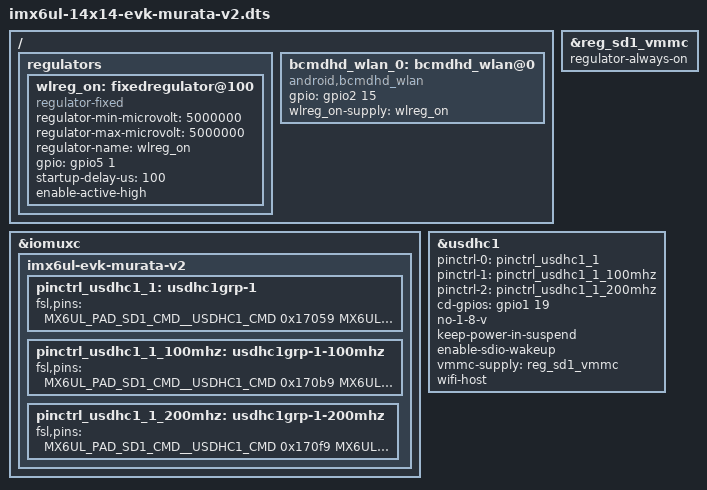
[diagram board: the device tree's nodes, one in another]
/*
 * Copyright (C) 2015 Freescale Semiconductor, Inc.
 *
 * This program is free software; you can redistribute it and/or modify
 * it under the terms of the GNU General Public License version 2 as
 * published by the Free Software Foundation.
 */

/* NOTE: This DTS file is written for plugging in Murata Wi-Fi/BT EVK into Slot SD1 */
/* and using Murata i.MX InterConnect Ver 2.0 Adapter. Bluetooth UART & control signals  */
/* are connected via ribbon cable (J1701 connector).  Default configuration does not enable OOB IRQ. */
/* If OOB IRQ (WL_HOST_WAKE) is needed then rework is required (reference Murata Hardware User Manual). */
#include "imx6ul-14x14-evk.dts"

/ {
	regulators {
		/* Murata -- add wlreg_on definition */
		wlreg_on: fixedregulator@100 {
			compatible = "regulator-fixed";
			regulator-min-microvolt = <5000000>;
			regulator-max-microvolt = <5000000>;
			regulator-name = "wlreg_on";
			gpio = <&gpio5 1 0>; /* WL_REG_ON: SNVS_TAMPER1 (gpio5_1) */
			startup-delay-us = <100>; /* WL_REG_ON needs 61 usec delay */ 
			enable-active-high;
		};
	};

	/* Murata -- define hook for BCMDHD driver.   */
	/* Include WL_HOST_WAKE and WL_REG_ON GPIO's. */
	bcmdhd_wlan_0: bcmdhd_wlan@0 {
		compatible = "android,bcmdhd_wlan";
		/* WL_HOST_WAKE: ENET2_RX_ER (gpio2_15) */
		gpio = <&gpio2 15 0>;
		wlreg_on-supply = <&wlreg_on>;
	};
};

&iomuxc {
	imx6ul-evk-murata-v2 {
		/* Murata -- modify MUXing to add WL_REG_ON and WL_HOST_WAKE for Ver 2.0 Adapter Only.  */ 
		/* Can add BT_HOST_WAKE and BT_DEV_WAKE later -- if rework done */
		/* Do not MUX WL_HOST_WAKE for now -- disrupts ethernet operation. */
		pinctrl_usdhc1_1: usdhc1grp-1 {
			fsl,pins = <
				MX6UL_PAD_SD1_CMD__USDHC1_CMD     0x17059
				MX6UL_PAD_SD1_CLK__USDHC1_CLK     0x10071 /* Murata: FSL Fix for drive strength; was 0x10059  */
				MX6UL_PAD_SD1_DATA0__USDHC1_DATA0 0x17059
				MX6UL_PAD_SD1_DATA1__USDHC1_DATA1 0x17059
				MX6UL_PAD_SD1_DATA2__USDHC1_DATA2 0x17059
				MX6UL_PAD_SD1_DATA3__USDHC1_DATA3 0x17059
				MX6UL_PAD_SNVS_TAMPER1__GPIO5_IO01 0x03029 /* Add MUXing for WL_REG_ON */
//				MX6UL_PAD_ENET2_RX_ER__GPIO2_IO15  0x13041 /* Add MUXing for WL_HOST_WAKE */
			>;
		};

		pinctrl_usdhc1_1_100mhz: usdhc1grp-1-100mhz {
			fsl,pins = <
				MX6UL_PAD_SD1_CMD__USDHC1_CMD     0x170b9
				MX6UL_PAD_SD1_CLK__USDHC1_CLK     0x100b9
				MX6UL_PAD_SD1_DATA0__USDHC1_DATA0 0x170b9
				MX6UL_PAD_SD1_DATA1__USDHC1_DATA1 0x170b9
				MX6UL_PAD_SD1_DATA2__USDHC1_DATA2 0x170b9
				MX6UL_PAD_SD1_DATA3__USDHC1_DATA3 0x170b9
				MX6UL_PAD_SNVS_TAMPER1__GPIO5_IO01 0x03029 /* Add MUXing for WL_REG_ON */
//				MX6UL_PAD_ENET2_RX_ER__GPIO2_IO15  0x13041 /* Add MUXing for WL_HOST_WAKE */
			>;
		};

		pinctrl_usdhc1_1_200mhz: usdhc1grp-1-200mhz {
			fsl,pins = <
				MX6UL_PAD_SD1_CMD__USDHC1_CMD     0x170f9
				MX6UL_PAD_SD1_CLK__USDHC1_CLK     0x100f9
				MX6UL_PAD_SD1_DATA0__USDHC1_DATA0 0x170f9
				MX6UL_PAD_SD1_DATA1__USDHC1_DATA1 0x170f9
				MX6UL_PAD_SD1_DATA2__USDHC1_DATA2 0x170f9
				MX6UL_PAD_SD1_DATA3__USDHC1_DATA3 0x170f9
				MX6UL_PAD_SNVS_TAMPER1__GPIO5_IO01 0x03029 /* Add MUXing for WL_REG_ON */
//				MX6UL_PAD_ENET2_RX_ER__GPIO2_IO15  0x13041 /* Add MUXing for WL_HOST_WAKE */
			>;
		};
	};
};

/* If using using WL_HOST_WAKE (with hardware mod), then FEC2 must be disabled. */
/* Temporary workaround just disable both FEC1 and FEC2.  - FIX LATER */
/* Commented out so that ethernet operation is still available. */
/*
&fec1 {
	status = "disabled";
}; 
&fec2 { 
	status = "disabled"; 
}; 
*/

/* force VMMC1 to always on so BT can operate independently of Wi-Fi */
&reg_sd1_vmmc{
	regulator-always-on;
};

/* Murata -- this is Wi-Fi/BT SD Card Slot Definition */
&usdhc1 {
	pinctrl-names = "default", "state_100mhz", "state_200mhz";
	pinctrl-0 = <&pinctrl_usdhc1_1>;
	pinctrl-1 = <&pinctrl_usdhc1_1_100mhz>;
	pinctrl-2 = <&pinctrl_usdhc1_1_200mhz>;
	cd-gpios = <&gpio1 19 0>;
	no-1-8-v; /* Murata -- fix VIO at 3.3V */
	keep-power-in-suspend;
	enable-sdio-wakeup;
	vmmc-supply = <&reg_sd1_vmmc>; 
	wifi-host; /* Murata -- add hook for SD card detect mechanism */
	status = "okay";
};
